# CEC1712H_N2_SX register map
Vendor: Microchip Technology; Series: CEC1712H_N2_SX; File version: 0
CPU: CM4 r1p0, little endian, no MPU, 3 interrupt priority bits, 172 interrupts
Registers are 32-bit, read-write, reset 0x0 unless marked. A register's access mark holds for its fields unless they carry their own. Offsets are from the block's base; [hi:lo] are bit positions; {n}, {i} and the like mark numbered series.

## TFDP — The TFDP serially transmits EC-originated diagnostic vectors to an external debug trace system.
Base 0x40008C00; register names take the prefix TFDP_
0x00 MSDATA 8-bit — Debug data to be shifted out on the TFDP Debug port. While data is being shifted out, the Host Interface will 'hold-off' additional writes to the data register until the transfer is complete.
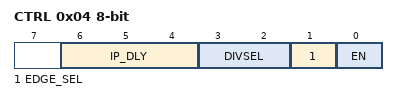
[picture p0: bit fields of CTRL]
0x04 CTRL 8-bit — Debug Control Register
  [6:4] IP_DLY — Inter-packet Delay. The delay is in terms of TFDP Debug output clocks.
  [3:2] DIVSEL — Clock Divider Select.
  [1] EDGE_SEL — 1= Data is shifted out on the falling edge of the debug clock, 0= Data is shifted out on the rising edge of the debug clock (Default)
  [0] EN — Enable. 1=Clock enabled, 0=Clock is disabled (Default)

## VBAT_RAM — The VBAT RAM is operational while the main power rail is operational, and will retain its values powered by battery power while the main rail is unpowered.
Base 0x4000A800; register names take the prefix VBAT_RAM_
{0x0+4i} MEM[{i}] (i=0..15) — 32-bits of VBAT powered RAM.

## VBAT — The VBAT Register Bank block is a block implemented for miscellaneous battery-backed registers
Base 0x4000A400; register names take the prefix VBAT_
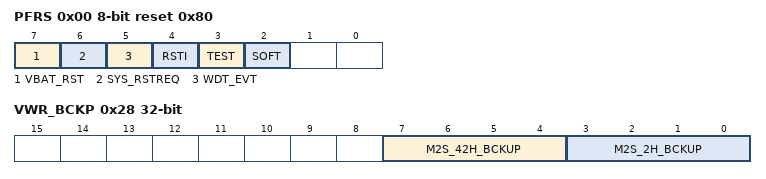
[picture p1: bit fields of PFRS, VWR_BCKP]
0x00 PFRS 8-bit reset 0x80 — The Power-Fail and Reset Status Register collects and retains the VBAT RST and WDT event status when VCC1 is unpowered.
  [7] VBAT_RST — The VBAT RST bit is set to '1' by hardware when a RESET_VBAT is detected. This is the register default value. To clear VBAT RST EC firmware must write a '1' to this bit; writing a '0' to VBAT RST has no affect.(R/WC)
  [6] SYS_RSTREQ — This bit is set to '1b' if a RESET_SYS was triggered by an ARM SYSRESETREQ event. This bit is cleared to '0b' when written with a '1b'; writes of a '0b' have no effect. (R/WC)
  [5] WDT_EVT — This bit is set to '1b' if a RESET_SYS was triggered by a Watchdog Timer event. This bit is cleared to '0b' when written with a '1b'; writes of a '0b' have no effect. (R/WC)
  [4] RSTI — This bit is set to '1b' if a RESET_SYS was triggered by a low signal on the RESETI# input pin. This bit is cleared to '0b' when written with a '1b'; writes of a '0b' have no effect. (R/WC)
  [3] TEST
  [2] SOFT — This bit is set to '1b' if a was triggered by an assertion of the SOFT_SYS_RESET bit in the System Reset Register. This bit is cleared to '0b' when written with a '1b'; writes of a '0b' have no effect. (R/WC)
0x08 CLK32_EN — CLOCK ENABLE
  [1] EXT_32K — This bit selects the source for the 32KHz clock domain. 1=The 32KHZ_IN VTR-powered pin is used as a source for the 32KHz clock domain. If an activity detector does not detect a clock on the selected source, the always-on 32KHz internal clock source is automatically selected. 0=The always-on32Khz clock source is used as the source for the 32KHz clock domain.
0x0C SYS_SHDN — System Shutdown Enable register.
  [0] DIS — This bit controls the System Shutdown. 0 = Enable System Shutdown (SYS_SHDN#). 1 = Disable System Shutdown (SYS_SHDN#).
0x20 MCNT_LO — MONOTONIC COUNTER
  [31:0] CNTR — Read-only register that increments by 1 every time it is read. It is reset to 0 on a VBAT Power On Reset.
0x24 MCNT_HI — COUNTER HIWORD
  [31:0] CNTR — Thirty-two bit read/write register. If software sets this register to an incrementing value, based on an external non-volatile store, this register may be combined with the Monotonic Counter Register to form a 64-bit monotonic counter.
0x28 VWR_BCKP — VWIRE_BACKUP
  [7:4] M2S_42H_BCKUP — The Boot ROM firmware will copy this field into the SRC3 to SRC0 bits of the Master-to-Slave Virtual Wire Register that corresponds to Virtual Wire Index 42h on a RESET_SYS. If software always saves the state of the Index 2h SRC bits on the falling edge of the SUSWARN# virtual wire, the state of the four SRC bits will be synchronized to the state of the four bits in the core logic.
  [3:0] M2S_2H_BCKUP — The Boot ROM firmware will copy this field into the SRC3 to SRC0 bits of the Master-to-Slave Virtual Wire Register that corresponds to Virtual Wire Index 2h on a RESET_SYS. If software always saves the state of the Index 2h SRC bits on the falling edge of the SUSWARN# virtual wire, the state of the four SRC bits will be synchronized to the state of the four bits in the core logic.

## OTP — OTP Programming registers.
Base 0x40082000; register names take the prefix OTP_

## NVIC — Nested Vectored Interrupt Controller
Base 0xE000E100; register names take the prefix NVIC_
{0x0+4i} ISER[{i}] (i=0..0) — Interrupt Set Enable Register
  [31:0] SETENA — Interrupt set enable bits
{0x80+4i} ICER[{i}] (i=0..0) — Interrupt Clear Enable Register
  [31:0] CLRENA — Interrupt clear-enable bits
{0x100+4i} ISPR[{i}] (i=0..0) — Interrupt Set Pending Register
  [31:0] SETPEND — Interrupt set-pending bits
{0x180+4i} ICPR[{i}] (i=0..0) — Interrupt Clear Pending Register
  [31:0] CLRPEND — Interrupt clear-pending bits
{0x200+4i} IABR[{i}] (i=0..0) — Interrupt Active Bit Register
  [31:0] ACTIVE — Interrupt active bits
{0x300+i} IP[{i}] (i=0..7) 8-bit — Interrupt Priority Register n
  [2:0] PRI0 — Priority of interrupt n
0xE00 STIR wo — Software Trigger Interrupt Register
  [8:0] INTID — Interrupt ID to trigger

## SysTick — System timer
Base 0xE000E010; register names take the prefix SysTick_
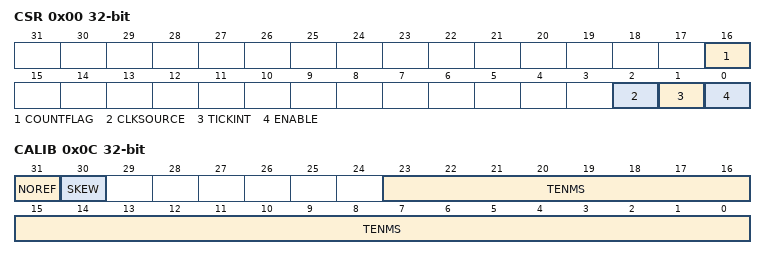
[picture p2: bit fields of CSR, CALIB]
0x00 CSR — SysTick Control and Status Register
  [16] COUNTFLAG — Timer counted to 0 since last read of register
  [2] CLKSOURCE — Clock Source 0=external, 1=processor
    0=External clock; 1=Processor clock
  [1] TICKINT — SysTick Exception Request Enable
    0=Counting down to 0 does not assert the SysTick exception request; 1=Counting down to 0 asserts the SysTick exception request
  [0] ENABLE — SysTick Counter Enable
    0=Counter disabled; 1=Counter enabled
0x04 RVR — SysTick Reload Value Register
  [23:0] RELOAD — Value to load into the SysTick Current Value Register when the counter reaches 0
0x08 CVR — SysTick Current Value Register
  [23:0] CURRENT — Current value at the time the register is accessed
0x0C CALIB ro — SysTick Calibration Value Register
  [31] NOREF — No Separate Reference Clock
    0=The reference clock is provided; 1=The reference clock is not provided
  [30] SKEW — TENMS is rounded from non-integer ratio
    0=10ms calibration value is exact; 1=10ms calibration value is inexact, because of the clock frequency
  [23:0] TENMS — Reload value to use for 10ms timing
